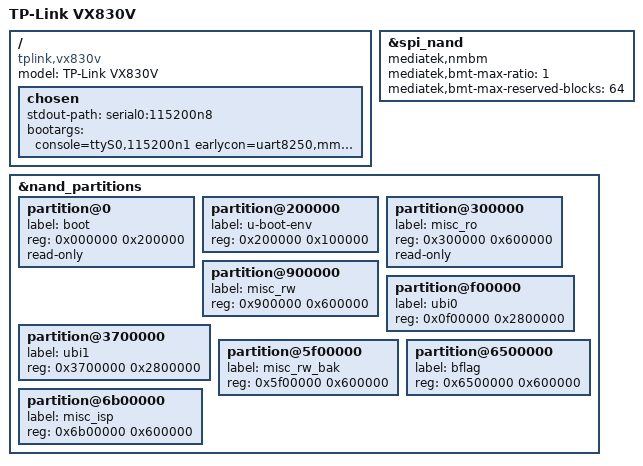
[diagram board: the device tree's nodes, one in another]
// SPDX-License-Identifier: GPL-2.0-or-later OR MIT
/*
 * Copyright (C) 2026 Alessandro <ciaomvv@gmail.com>
 */

/dts-v1/;

#include "mt7986a-tplink-vx830v-common.dtsi"

/ {
	model = "TP-Link VX830V";
	compatible = "tplink,vx830v", "mediatek,mt7986a";

	chosen {
		stdout-path = "serial0:115200n8";
		bootargs = "console=ttyS0,115200n1 earlycon=uart8250,mmio32,0x11002000 ubi.mtd=ubi0";
	};
};

&spi_nand {
	mediatek,nmbm;
	mediatek,bmt-max-ratio = <1>;
	mediatek,bmt-max-reserved-blocks = <64>;
};

&nand_partitions {

	partition@0 {
		label = "boot";
		reg = <0x000000 0x200000>;
		read-only;
	};

	partition@200000 {
		label = "u-boot-env";
		reg = <0x200000 0x100000>;
	};

	partition@300000 {
		label = "misc_ro";
		reg = <0x300000 0x600000>;
		read-only;
	};

	partition@900000 {
		label = "misc_rw";
		reg = <0x900000 0x600000>;
	};

	partition@f00000 {
		label = "ubi0";
		reg = <0x0f00000 0x2800000>;
	};

	partition@3700000 {
		label = "ubi1";
		reg = <0x3700000 0x2800000>;
	};

	partition@5f00000 {
		label = "misc_rw_bak";
		reg = <0x5f00000 0x600000>;
	};

	partition@6500000 {
		label = "bflag";
		reg = <0x6500000 0x600000>;
	};

	partition@6b00000 {
		label = "misc_isp";
		reg = <0x6b00000 0x600000>;
	};
};
